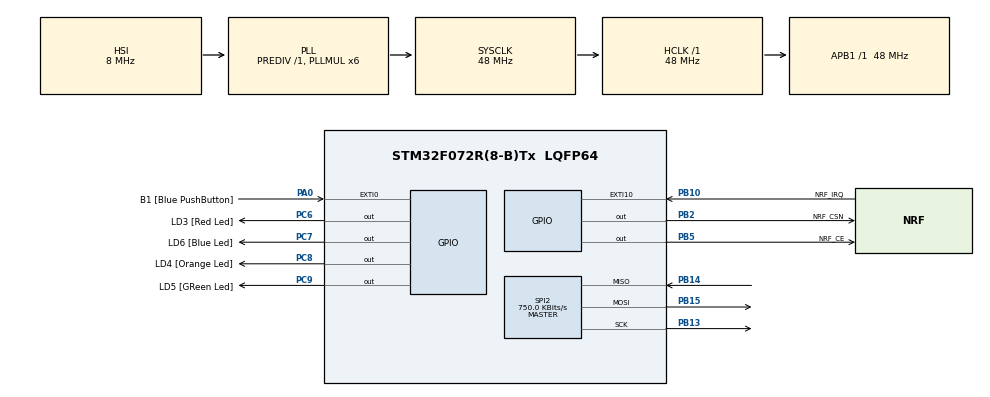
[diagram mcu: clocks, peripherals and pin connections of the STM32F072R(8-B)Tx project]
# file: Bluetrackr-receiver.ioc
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Mcu.Family=STM32F0
Mcu.Name=STM32F072R(8-B)Tx
Mcu.Package=LQFP64
PA0.GPIO_Label=B1 [Blue PushButton]
PA0.GPIO_ModeDefaultEXTI=GPIO_MODE_EVT_RISING
PA0.Signal=GPXTI0
PA13.GPIO_Label=SWDIO
PA13.Mode=Serial_Wire
PA13.Signal=SYS_SWDIO
PA14.GPIO_Label=SWCLK
PA14.Mode=Serial_Wire
PA14.Signal=SYS_SWCLK
PB10.GPIO_Label=NRF_IRQ
PB10.Signal=GPXTI10
PB13.Mode=Full_Duplex_Master
PB13.Signal=SPI2_SCK
PB14.Mode=Full_Duplex_Master
PB14.Signal=SPI2_MISO
PB15.Mode=Full_Duplex_Master
PB15.Signal=SPI2_MOSI
PB2.GPIO_Label=NRF_CSN
PB2.Signal=GPIO_Output
PB5.GPIO_Label=NRF_CE
PB5.Signal=GPIO_Output
PC6.GPIO_Label=LD3 [Red Led]
PC6.Signal=GPIO_Output
PC7.GPIO_Label=LD6 [Blue Led]
PC7.Signal=GPIO_Output
PC8.GPIO_Label=LD4 [Orange Led]
PC8.Signal=GPIO_Output
PC9.GPIO_Label=LD5 [GReen Led]
PC9.Signal=GPIO_Output
ProjectManager.HeapSize=0x200
ProjectManager.StackSize=0x400
ProjectManager.TargetToolchain=Other Toolchains (GPDSC)
RCC.AHBFreq_Value=48000000
RCC.APB1Freq_Value=48000000
RCC.APB1TimFreq_Value=48000000
RCC.HCLKFreq_Value=48000000
RCC.PLLMUL=RCC_PLL_MUL6
RCC.SYSCLKFreq_VALUE=48000000
RCC.SYSCLKSource=RCC_SYSCLKSOURCE_PLLCLK
SPI2.BaudRatePrescaler=SPI_BAUDRATEPRESCALER_64
SPI2.CalculateBaudRate=750.0 KBits/s
SPI2.DataSize=SPI_DATASIZE_8BIT
SPI2.Direction=SPI_DIRECTION_2LINES
SPI2.Mode=SPI_MODE_MASTER
SPI2.NSSPMode=SPI_NSS_PULSE_DISABLE
SPI2.VirtualType=VM_MASTER
board=STM32F072B-DISCO

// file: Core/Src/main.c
/* USER CODE BEGIN Header */
/**
 ******************************************************************************
 * @file           : main.c
 * @brief          : Main program body
 ******************************************************************************
 * @attention
 *
 * <h2><center>&copy; Copyright (c) 2019 STMicroelectronics.
 * All rights reserved.</center></h2>
 *
 * This software component is licensed by ST under BSD 3-Clause license,
 * the "License"; You may not use this file except in compliance with the
 * License. You may obtain a copy of the License at:
 *                        opensource.org/licenses/BSD-3-Clause
 *
 ******************************************************************************
 */
/* USER CODE END Header */

#include "main.h"

/* USER CODE BEGIN Includes */
#include "main_loop.h"
/* USER CODE END Includes */

SPI_HandleTypeDef hspi2;

void SystemClock_Config(void);
static void MX_GPIO_Init(void);
static void MX_SPI2_Init(void);

int main(void)
{

  /* MCU Configuration--------------------------------------------------------*/

  /* Reset of all peripherals, Initializes the Flash interface and the Systick. */
  HAL_Init();

  /* Configure the system clock */
  SystemClock_Config();

  /* Initialize all configured peripherals */
  MX_GPIO_Init();
  MX_SPI2_Init();
  /* USER CODE BEGIN 2 */
  main_loop(&hspi2);
  /* USER CODE END 2 */

  /* Infinite loop */
  while (1) {

  }
}

void SystemClock_Config(void)
{
  RCC_OscInitTypeDef RCC_OscInitStruct = {0};
  RCC_ClkInitTypeDef RCC_ClkInitStruct = {0};

  /** Initializes the CPU, AHB and APB busses clocks
  */
  RCC_OscInitStruct.OscillatorType = RCC_OSCILLATORTYPE_HSI;
  RCC_OscInitStruct.HSIState = RCC_HSI_ON;
  RCC_OscInitStruct.HSICalibrationValue = RCC_HSICALIBRATION_DEFAULT;
  RCC_OscInitStruct.PLL.PLLState = RCC_PLL_ON;
  RCC_OscInitStruct.PLL.PLLSource = RCC_PLLSOURCE_HSI;
  RCC_OscInitStruct.PLL.PLLMUL = RCC_PLL_MUL6;
  RCC_OscInitStruct.PLL.PREDIV = RCC_PREDIV_DIV1;
  if (HAL_RCC_OscConfig(&RCC_OscInitStruct) != HAL_OK)
  {
    Error_Handler();
  }
  /** Initializes the CPU, AHB and APB busses clocks
  */
  RCC_ClkInitStruct.ClockType = RCC_CLOCKTYPE_HCLK|RCC_CLOCKTYPE_SYSCLK
                              |RCC_CLOCKTYPE_PCLK1;
  RCC_ClkInitStruct.SYSCLKSource = RCC_SYSCLKSOURCE_PLLCLK;
  RCC_ClkInitStruct.AHBCLKDivider = RCC_SYSCLK_DIV1;
  RCC_ClkInitStruct.APB1CLKDivider = RCC_HCLK_DIV1;

  if (HAL_RCC_ClockConfig(&RCC_ClkInitStruct, FLASH_LATENCY_1) != HAL_OK)
  {
    Error_Handler();
  }
}

static void MX_SPI2_Init(void)
{

  /* SPI2 parameter configuration*/
  hspi2.Instance = SPI2;
  hspi2.Init.Mode = SPI_MODE_MASTER;
  hspi2.Init.Direction = SPI_DIRECTION_2LINES;
  hspi2.Init.DataSize = SPI_DATASIZE_8BIT;
  hspi2.Init.CLKPolarity = SPI_POLARITY_LOW;
  hspi2.Init.CLKPhase = SPI_PHASE_1EDGE;
  hspi2.Init.NSS = SPI_NSS_SOFT;
  hspi2.Init.BaudRatePrescaler = SPI_BAUDRATEPRESCALER_64;
  hspi2.Init.FirstBit = SPI_FIRSTBIT_MSB;
  hspi2.Init.TIMode = SPI_TIMODE_DISABLE;
  hspi2.Init.CRCCalculation = SPI_CRCCALCULATION_DISABLE;
  hspi2.Init.CRCPolynomial = 7;
  hspi2.Init.CRCLength = SPI_CRC_LENGTH_DATASIZE;
  hspi2.Init.NSSPMode = SPI_NSS_PULSE_DISABLE;
  if (HAL_SPI_Init(&hspi2) != HAL_OK)
  {
    Error_Handler();
  }

}

static void MX_GPIO_Init(void)
{
  GPIO_InitTypeDef GPIO_InitStruct = {0};

  /* GPIO Ports Clock Enable */
  __HAL_RCC_GPIOA_CLK_ENABLE();
  __HAL_RCC_GPIOB_CLK_ENABLE();
  __HAL_RCC_GPIOC_CLK_ENABLE();

  /*Configure GPIO pin Output Level */
  HAL_GPIO_WritePin(GPIOB, NRF_CSN_Pin|NRF_CE_Pin, GPIO_PIN_RESET);

  /*Configure GPIO pin Output Level */
  HAL_GPIO_WritePin(GPIOC, LD3_Pin|LD6_Pin|LD4_Pin|LD5_Pin, GPIO_PIN_RESET);

  /*Configure GPIO pin : B1_Pin */
  GPIO_InitStruct.Pin = B1_Pin;
  GPIO_InitStruct.Mode = GPIO_MODE_EVT_RISING;
  GPIO_InitStruct.Pull = GPIO_NOPULL;
  HAL_GPIO_Init(B1_GPIO_Port, &GPIO_InitStruct);

  /*Configure GPIO pins : NRF_CSN_Pin NRF_CE_Pin */
  GPIO_InitStruct.Pin = NRF_CSN_Pin|NRF_CE_Pin;
  GPIO_InitStruct.Mode = GPIO_MODE_OUTPUT_PP;
  GPIO_InitStruct.Pull = GPIO_NOPULL;
  GPIO_InitStruct.Speed = GPIO_SPEED_FREQ_LOW;
  HAL_GPIO_Init(GPIOB, &GPIO_InitStruct);

  /*Configure GPIO pin : NRF_IRQ_Pin */
  GPIO_InitStruct.Pin = NRF_IRQ_Pin;
  GPIO_InitStruct.Mode = GPIO_MODE_IT_RISING;
  GPIO_InitStruct.Pull = GPIO_NOPULL;
  HAL_GPIO_Init(NRF_IRQ_GPIO_Port, &GPIO_InitStruct);

  /*Configure GPIO pins : LD3_Pin LD6_Pin LD4_Pin LD5_Pin */
  GPIO_InitStruct.Pin = LD3_Pin|LD6_Pin|LD4_Pin|LD5_Pin;
  GPIO_InitStruct.Mode = GPIO_MODE_OUTPUT_PP;
  GPIO_InitStruct.Pull = GPIO_NOPULL;
  GPIO_InitStruct.Speed = GPIO_SPEED_FREQ_LOW;
  HAL_GPIO_Init(GPIOC, &GPIO_InitStruct);

}

void Error_Handler(void)
{
}

/************************ (C) COPYRIGHT STMicroelectronics *****END OF FILE****/
